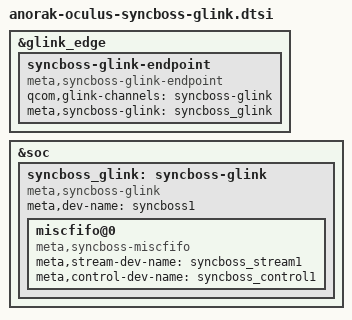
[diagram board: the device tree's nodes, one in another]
// SPDX-License-Identifier: GPL-2.0

&glink_edge {
	syncboss-glink-endpoint {
		compatible = "meta,syncboss-glink-endpoint";
		qcom,glink-channels = "syncboss-glink";
		meta,syncboss-glink = <&syncboss_glink>;
	};
};

&soc {
	syncboss_glink: syncboss-glink {
		compatible = "meta,syncboss-glink";
		meta,dev-name = "syncboss1";

		miscfifo@0 {
			compatible = "meta,syncboss-miscfifo", "meta,syncboss-consumer";
			meta,stream-dev-name = "syncboss_stream1";
			meta,control-dev-name = "syncboss_control1";
		};
	};
};
